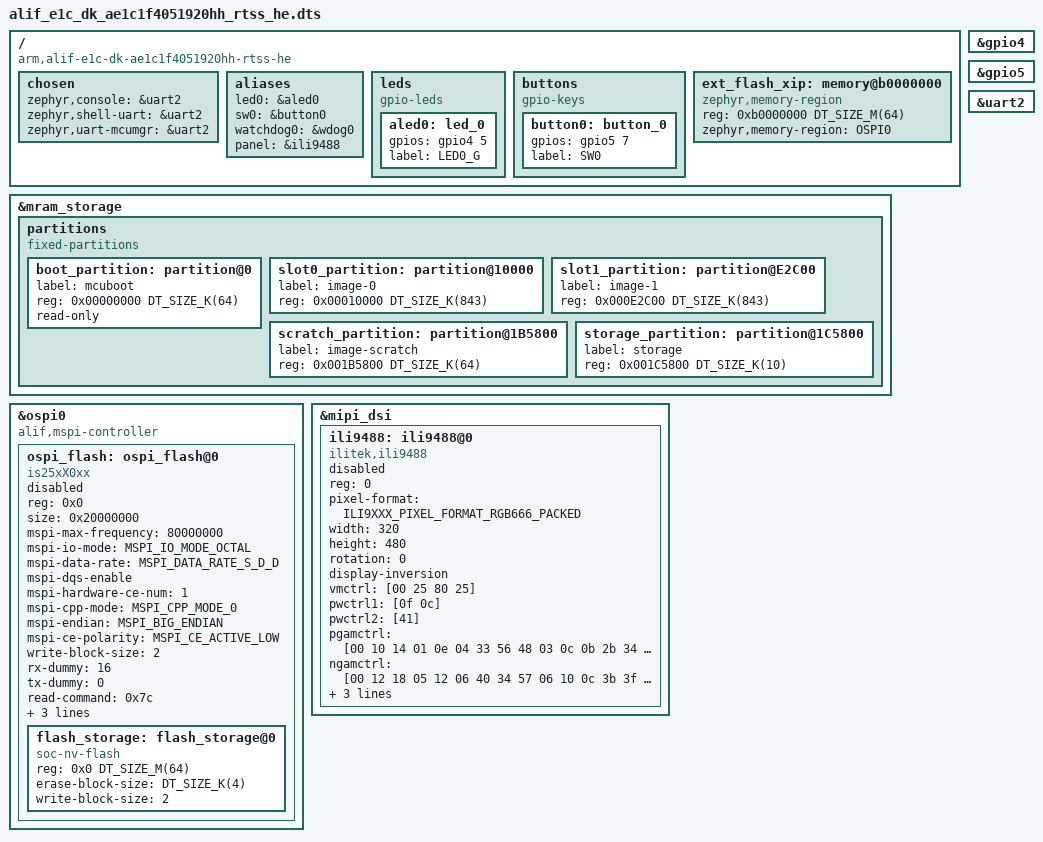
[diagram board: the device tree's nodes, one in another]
/* Copyright (c) 2025 Alif Semiconductor
 *
 * SPDX-License-Identifier: Apache-2.0
 */

/dts-v1/;

#include <alif/ensemble/e1c/ae1c1f4051920hh.dtsi>
#include "../common/ensemble-e1c-pinctrl.dtsi"
#include "../common/balletto-sd-vsel.dtsi"
#include <zephyr/dt-bindings/display/ili9xxx.h>

/ {
	compatible = "arm,alif-e1c-dk-ae1c1f4051920hh-rtss-he";
	#address-cells = <1>;
	#size-cells = <1>;

	chosen {
		zephyr,console = &uart2;
		zephyr,shell-uart = &uart2;
		zephyr,uart-mcumgr = &uart2;
	};

	aliases {
		led0 = &aled0;
		sw0 = &button0;
		watchdog0 = &wdog0;
		panel = &ili9488;
	};

	leds {
		compatible = "gpio-leds";

		aled0: led_0 {
			gpios = <&gpio4 5 0>;
			label = "LED0_G";
		};
	};

	buttons {
		compatible = "gpio-keys";

		button0: button_0 {
			gpios = < &gpio5 7 0 >;
			label = "SW0";
		};
	};

	ext_flash_xip: memory@b0000000 {
		compatible = "zephyr,memory-region";
		reg = <0xb0000000 DT_SIZE_M(64)>;
		zephyr,memory-region = "OSPI0";
	};
};

&gpio4 {
	status = "okay";
};

&gpio5 {
	status = "okay";
};

&uart2 {
	status = "okay";
};

&mram_storage {
	partitions {
		compatible = "fixed-partitions";
		#address-cells = <1>;
		#size-cells = <1>;

		boot_partition: partition@0 {
			label = "mcuboot";
			reg = <0x00000000 DT_SIZE_K(64)>;
			read-only;
		};

		slot0_partition: partition@10000 {
			label = "image-0";
			reg = <0x00010000 DT_SIZE_K(843)>;
		};

		slot1_partition: partition@E2C00 {
			label = "image-1";
			reg = <0x000E2C00 DT_SIZE_K(843)>;
		};

		scratch_partition: partition@1B5800 {
			label = "image-scratch";
			reg = <0x001B5800 DT_SIZE_K(64)>;
		};

		storage_partition: partition@1C5800 {
			label = "storage";
			reg = <0x001C5800 DT_SIZE_K(10)>;
		};
	};
};

&ospi0 {
	compatible = "alif,mspi-controller", "snps,designware-ssi";

	/* External Flash on OSPI */
	ospi_flash: ospi_flash@0 {
		compatible = "is25xX0xx";
		reg = <0x0>;
		size = <0x20000000>;
		mspi-max-frequency = <80000000>;
		mspi-io-mode = "MSPI_IO_MODE_OCTAL";
		mspi-data-rate = "MSPI_DATA_RATE_S_D_D";
		mspi-dqs-enable;
		mspi-hardware-ce-num = <1>;
		mspi-cpp-mode = "MSPI_CPP_MODE_0";
		mspi-endian = "MSPI_BIG_ENDIAN";
		mspi-ce-polarity = "MSPI_CE_ACTIVE_LOW";
		write-block-size = <2>;
		rx-dummy = <16>;
		tx-dummy = <0>;
		read-command = <0x7c>;
		write-command = <0x84>;
		command-length = "INSTR_1_BYTE";
		address-length = "ADDR_4_BYTE";

		/* Flash Size 64MB */
		#address-cells = <1>;
		#size-cells = <1>;

		flash_storage: flash_storage@0 {
			compatible = "soc-nv-flash";
			reg = <0x0 DT_SIZE_M(64)>;
			erase-block-size = <DT_SIZE_K(4)>;
			write-block-size = <2>;
		};
		status = "disabled";
	};
};

&mipi_dsi {
		ili9488: ili9488@0 {
			compatible = "ilitek,ili9488";
			reg = <0>;
			pixel-format = <ILI9XXX_PIXEL_FORMAT_RGB666_PACKED>;
			width = <320>;
			height = <480>;
			rotation = <0>;

			display-inversion;

			vmctrl = [00 25 80 25];
			pwctrl1 = [0f 0c];
			pwctrl2 = [41];
			pgamctrl = [00 10 14 01 0e 04 33 56 48 03 0c 0b 2b 34 0f];
			ngamctrl = [00 12 18 05 12 06 40 34 57 06 10 0c 3b 3f 0f];
			data-lanes = <1>;
			reset-gpios = <&gpio8 0 GPIO_ACTIVE_LOW>;
			bl-gpios = <&gpio8 1 GPIO_ACTIVE_HIGH>;
			status = "disabled";
		};
};
